# ballast register map
Vendor: tuni.fi; File version: 1.0
CPU: other r1p0, little endian, MPU, no FPU, vendor SysTick, 3 interrupt priority bits
Registers are 32-bit, read-only, no defined reset value unless marked. A register's access mark holds for its fields unless they carry their own. Offsets are from the block's base; lines under a group give offsets from that group; [hi:lo] are bit positions; {n}, {i} and the like mark numbered series; 'fields as' and 'values as' point back to an identical list; <NAME> marks a mode.

## Memory map
0x00000000 TLP blocks up to offset 0x800
0x0D000000 DSP blocks up to offset 0x328 — Stores different status information about the core
0x0E000000 ethernet blocks up to offset 0x230
0x0F000000 AI blocks up to offset 0xC000
0x1A000000 MPC blocks up to offset 0x111000
0x20000000 SYSCTRL blocks up to offset 0x121000
0x40000000 C2C

## DSP — Stores different status information about the core
Base 0x0D000000
0x00 status_registers group
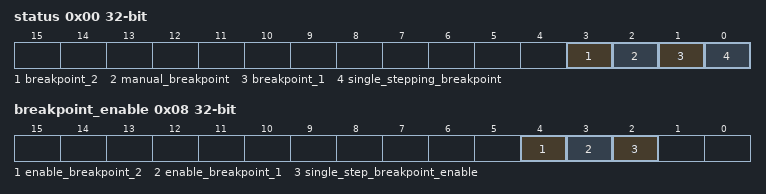
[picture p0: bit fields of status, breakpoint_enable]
  0x00 status — Status: Shows why the TTA core is in a break state Bit 0: single-stepping breakpoint Bit 1: Breakpoint 1 Bit 2: Breakpoint 2 Bit 3: Manual breakpoint
    [3] breakpoint_2, [2] manual_breakpoint, [1] breakpoint_1, [0] single_stepping_breakpoint
  0x04 program_counter
  0x08 cycle_count_low — Low part of Cycle count register
    [31:0] cycle_count_low — Cycle count (low 32 bits)
  0x0C cycle_count_high — High part of Cycle count register
    [31:0] cycle_count_high — Cycle count (high 32 bits)
  0x10 stall_count_low — Low part of Stall count
    [31:0] stall_count_low — Stall count (low 32 bits)
  0x14 stall_count_high — High part of Stall count
0x40 bus_trace_registers group
  0x00 bus_trace_reg_0
    [31:0] bus_trace_reg_1
  0x04 bus_trace_reg_1
    [31:0] bus_trace_reg_2
  {0x0+4j} bus_trace_reg_{j} (j=2..4)
0x200 control_registers group
  0x00 command wo — Command (1 = reset, 2 = run, 4 = break)
  0x04 start_address rw
    [31:0] start_address — star
  0x08 breakpoint_enable rw — Breakpoint enable Bit 0-1: Reserved Bit 2: Enable single-stepping breakpoint Bit 3: Enable breakpoint 1 Bit 3: Enable breakpoint 2
    [4] enable_breakpoint_2, [3] enable_breakpoint_1, [2] single_step_breakpoint_enable
  0x0C cycle_count_breakpoint access not given
  0x10 breakpoint_2_addr rw
  0x14 breakpoint_1_addr rw
0x300 processor_info_registers group
  0x00 device_class — Device class (0x774)
  0x04 device_id — Device ID (unimplemented)
  0x08 interface_version — Interface version (0x2)
  0x0C core_count
  0x10 ctrl_size — CTRL size, per core, in bytes
  0x14 data_mem_size — Data memory size, in bytes
  0x18 instr_mem_size — Instruction memory size, in bytes
  0x1C param_mem_size — Parameter memory size, in bytes
  0x20 debug_feature_support — Debug feature support (0x1)
  0x24 breakpoint_count — Breakpoint count (0x2)

## TLP
Base 0x00000000
0x00 Apb_software_irq group
  0x00 software_irq_read 16-bit
  0x04 software_irq_set 16-bit wo
  0x08 software_irq_clear 16-bit wo
0x200 Global_intr_router group
  {0x0+4j} irq_{j}_route_reg_0 8-bit rw reset 0x1 (reset mask 0x0) (j=0..2)
    [4:0] irq_{j}_route_reg_0
  0x0C irq_0_route_reg_1 8-bit rw
    [4:0] irq_0_route_reg_1
  {0x4+0xC*j} irq_1_route_reg_{j} 8-bit rw (j=1..6)
    [4:0] irq_1_route_reg_{j}
  {0x8+0xC*j} irq_2_route_reg_{j} 8-bit rw (j=1..3)
    [4:0] irq_2_route_reg_{j}
  0x18 irq_0_route_reg_2 8-bit rw
    [4:0] irq_0_route_reg_2
0x400 C2C_remap group
  0x00 c2c_remap_tx_addr rw
  0x04 c2c_remap_tx_mask rw
  0x08 c2c_remap_rx_addr rw
  0x0C c2c_remap_rx_mask rw
0x600 Pad_config group
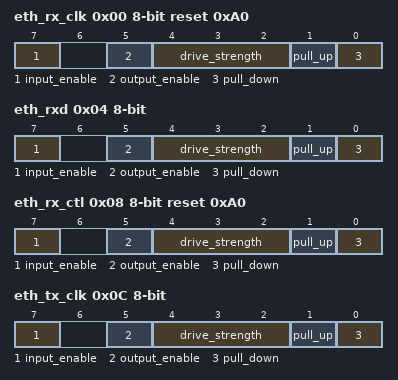
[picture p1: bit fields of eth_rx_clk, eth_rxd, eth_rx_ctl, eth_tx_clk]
  0x00 eth_rx_clk 8-bit rw reset 0xA0 (reset mask 0x0)
    [7] input_enable, [5] output_enable, [4:2] drive_strength, [1] pull_up, [0] pull_down
  0x04 eth_rxd 8-bit rw
    fields as Pad_config.eth_rx_clk
  0x08 eth_rx_ctl 8-bit rw reset 0xA0 (reset mask 0x0)
    fields as Pad_config.eth_rx_clk
  0x0C eth_tx_clk 8-bit rw
    fields as Pad_config.eth_rx_clk
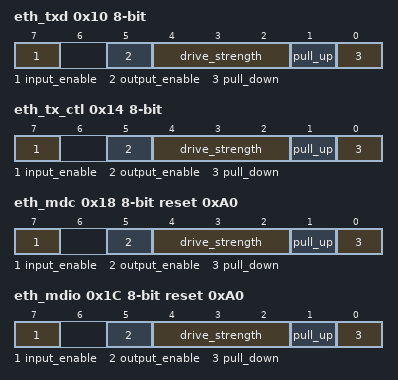
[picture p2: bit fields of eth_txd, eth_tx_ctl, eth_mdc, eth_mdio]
  0x10 eth_txd 8-bit rw
    fields as Pad_config.eth_rx_clk
  0x14 eth_tx_ctl 8-bit rw
    fields as Pad_config.eth_rx_clk
  0x18 eth_mdc 8-bit rw reset 0xA0 (reset mask 0x0)
    fields as Pad_config.eth_rx_clk
  0x1C eth_mdio 8-bit rw reset 0xA0 (reset mask 0x0)
    [7] input_enable ro, [5] output_enable ro, [4:2] drive_strength, [1] pull_up, [0] pull_down
  0x20 c2c_tx_ack 10-bit rw reset 0x200 (reset mask 0x0)
    [9] input_enable
    [8] pull_down_up — Pull down 0 Pull up 1
    [7] pull_enable
    [5] output_enable
    [1:0] drive_strength
  0x24 c2c_tx_vld 10-bit rw
    fields as Pad_config.c2c_tx_ack
  0x28 c2c_tx_d 10-bit rw reset 0x200 (reset mask 0x0)
    fields as Pad_config.c2c_tx_ack
  0x2C c2c_rx_ack 10-bit rw
    fields as Pad_config.c2c_tx_ack
  0x30 c2c_rx_vld 10-bit rw reset 0x200 (reset mask 0x0)
    fields as Pad_config.c2c_tx_ack
  0x34 c2c_rx_d 10-bit rw
    fields as Pad_config.c2c_tx_ack
  0x38 rst_mstr 10-bit rw reset 0x200 (reset mask 0x0)
    [9] input_enable ro
    [8] pull_down_up — Pull down 0 Pull up 1
    [7] pull_enable
    [5] output_enable ro
    [1:0] drive_strength
  0x3C rst_slv 10-bit rw reset 0x200 (reset mask 0x0)
    fields as Pad_config.rst_mstr
  0x40 refclk 4-bit rw reset 0xF (reset mask 0x0)
    [3] enable, [2:0] drive_strength
